# iom480ae register map
Registers are 32-bit, access not given, no defined reset value unless marked. A register's access mark holds for its fields unless they carry their own. Addresses are absolute; registers are grouped by the start of their names; [hi:lo] are bit positions; {n}, {i} and the like mark numbered series; 'fields as' and 'values as' point back to an identical list.

## SCS
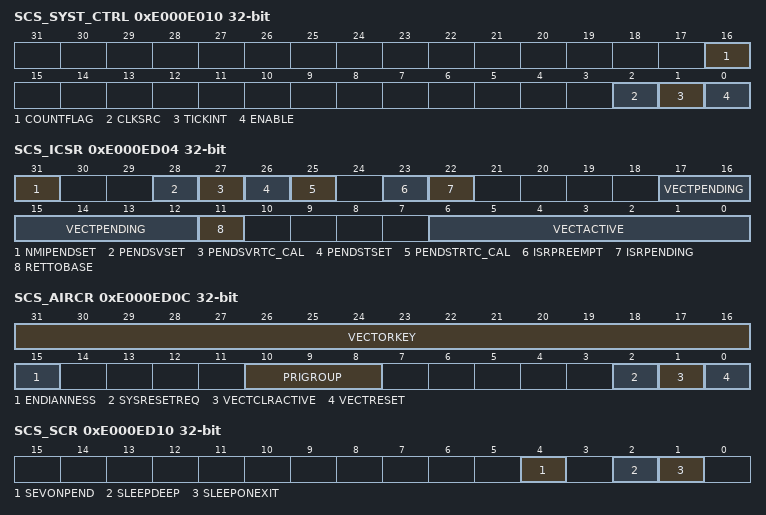
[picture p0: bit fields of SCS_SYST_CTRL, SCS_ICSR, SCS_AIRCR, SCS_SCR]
0xE000E010 SCS_SYST_CTRL
  [16] COUNTFLAG, [2] CLKSRC, [1] TICKINT, [0] ENABLE
0xE000E014 SCS_SYST_LOAD
  [23:0] RELOAD
0xE000E018 SCS_SYST_VAL
  [23:0] CURRENT
0xE000ED04 SCS_ICSR
  [31] NMIPENDSET, [28] PENDSVSET, [27] PENDSVRTC_CAL, [26] PENDSTSET, [25] PENDSTRTC_CAL, [23] ISRPREEMPT, [22] ISRPENDING, [17:12] VECTPENDING, [11] RETTOBASE, [6:0] VECTACTIVE
0xE000ED0C SCS_AIRCR
  [31:16] VECTORKEY, [15] ENDIANNESS, [10:8] PRIGROUP, [2] SYSRESETREQ, [1] VECTCLRACTIVE, [0] VECTRESET
0xE000ED10 SCS_SCR
  [4] SEVONPEND, [2] SLEEPDEEP, [1] SLEEPONEXIT
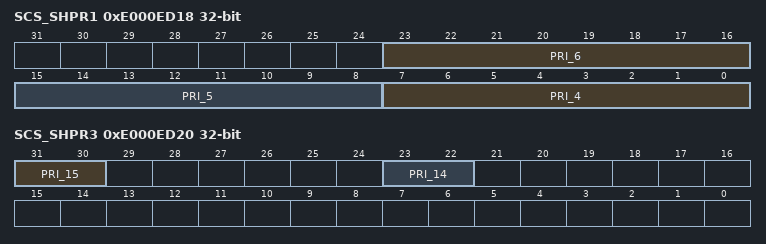
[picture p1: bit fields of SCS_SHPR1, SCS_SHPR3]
0xE000ED18 SCS_SHPR1
  [23:16] PRI_6, [15:8] PRI_5, [7:0] PRI_4
0xE000ED1C SCS_SHPR2
  [31:30] PRI_11
0xE000ED20 SCS_SHPR3
  [31:30] PRI_15, [23:22] PRI_14

## NVIC
{0xE000E100+4i} NVIC_NVIC_ISER{i} (i=0..2)
{0xE000E180+4i} NVIC_NVIC_ICER{i} (i=0..2)
{0xE000E200+4i} NVIC_NVIC_ISPR{i} (i=0..2)
{0xE000E280+4i} NVIC_NVIC_ICPR{i} (i=0..2)
{0xE000E300+4i} NVIC_NVIC_IABR{i} (i=0..2)
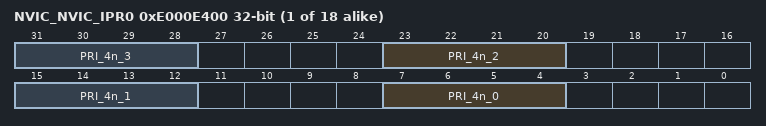
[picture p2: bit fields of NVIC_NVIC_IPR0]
{0xE000E400+4i} NVIC_NVIC_IPR{i} (i=0..17)
  [8n+7:8n+4] PRI_4n_{n} (n=0..3)
0xE000EF00 NVIC_STIR
  [8:0] INTID

## NMI
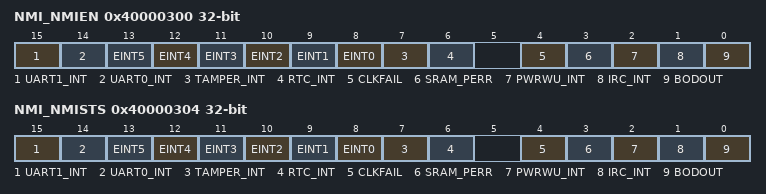
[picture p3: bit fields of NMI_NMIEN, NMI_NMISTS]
0x40000300 NMI_NMIEN
  [15] UART1_INT, [14] UART0_INT, [n+8] EINT{n} (n=0..5), [7] TAMPER_INT, [6] RTC_INT, [4] CLKFAIL, [3] SRAM_PERR, [2] PWRWU_INT, [1] IRC_INT, [0] BODOUT
0x40000304 NMI_NMISTS
  fields as NMI_NMIEN

## CLK
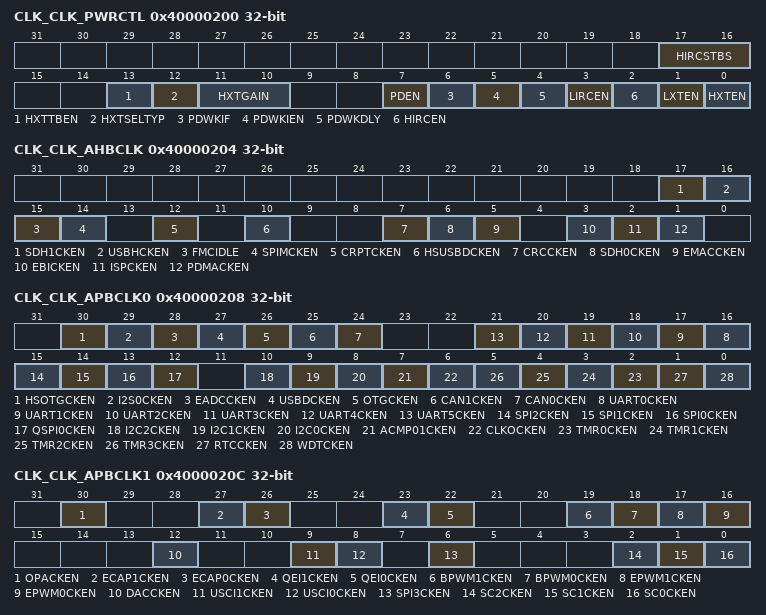
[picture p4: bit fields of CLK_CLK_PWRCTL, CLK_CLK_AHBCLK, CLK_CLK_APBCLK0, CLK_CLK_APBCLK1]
0x40000200 CLK_CLK_PWRCTL
  [17:16] HIRCSTBS, [13] HXTTBEN, [12] HXTSELTYP, [11:10] HXTGAIN, [7] PDEN, [6] PDWKIF, [5] PDWKIEN, [4] PDWKDLY, [3] LIRCEN, [2] HIRCEN, [1] LXTEN, [0] HXTEN
0x40000204 CLK_CLK_AHBCLK
  [17] SDH1CKEN, [16] USBHCKEN, [15] FMCIDLE, [14] SPIMCKEN, [12] CRPTCKEN, [10] HSUSBDCKEN, [7] CRCCKEN, [6] SDH0CKEN, [5] EMACCKEN, [3] EBICKEN, [2] ISPCKEN, [1] PDMACKEN
0x40000208 CLK_CLK_APBCLK0
  [30] HSOTGCKEN, [29] I2S0CKEN, [28] EADCCKEN, [27] USBDCKEN, [26] OTGCKEN, [25] CAN1CKEN, [24] CAN0CKEN, [n+16] UART{n}CKEN (n=0..5), [15] SPI2CKEN, [14] SPI1CKEN, [13] SPI0CKEN, [12] QSPI0CKEN, [10] I2C2CKEN, [9] I2C1CKEN, [8] I2C0CKEN, [7] ACMP01CKEN, [6] CLKOCKEN, [n+2] TMR{n}CKEN (n=0..3), [1] RTCCKEN, [0] WDTCKEN
0x4000020C CLK_CLK_APBCLK1
  [30] OPACKEN, [27] ECAP1CKEN, [26] ECAP0CKEN, [23] QEI1CKEN, [22] QEI0CKEN, [19] BPWM1CKEN, [18] BPWM0CKEN, [17] EPWM1CKEN, [16] EPWM0CKEN, [12] DACCKEN, [9] USCI1CKEN, [8] USCI0CKEN, [6] SPI3CKEN, [2] SC2CKEN, [1] SC1CKEN, [0] SC0CKEN
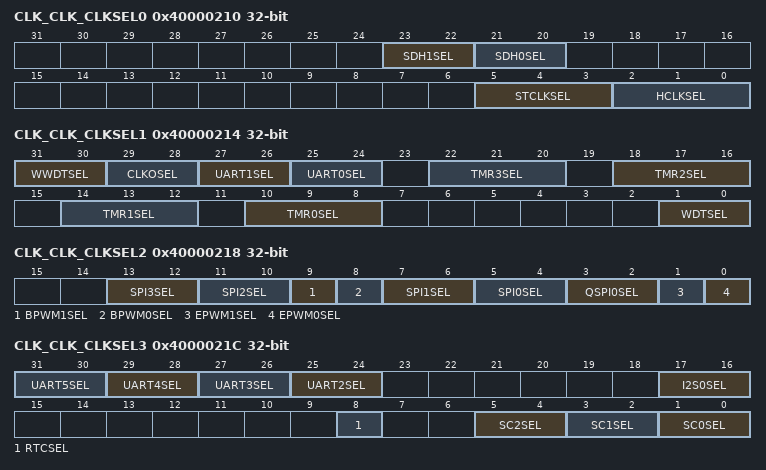
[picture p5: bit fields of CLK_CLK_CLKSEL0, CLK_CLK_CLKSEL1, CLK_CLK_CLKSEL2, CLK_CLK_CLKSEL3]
0x40000210 CLK_CLK_CLKSEL0
  [23:22] SDH1SEL, [21:20] SDH0SEL, [5:3] STCLKSEL, [2:0] HCLKSEL
0x40000214 CLK_CLK_CLKSEL1
  [31:30] WWDTSEL, [29:28] CLKOSEL, [27:26] UART1SEL, [25:24] UART0SEL, [4n+10:4n+8] TMR{n}SEL (n=0..3), [1:0] WDTSEL
0x40000218 CLK_CLK_CLKSEL2
  [13:12] SPI3SEL, [11:10] SPI2SEL, [9] BPWM1SEL, [8] BPWM0SEL, [7:6] SPI1SEL, [5:4] SPI0SEL, [3:2] QSPI0SEL, [1] EPWM1SEL, [0] EPWM0SEL
0x4000021C CLK_CLK_CLKSEL3
  [2n+21:2n+20] UART{n}SEL (n=2..5), [17:16] I2S0SEL, [8] RTCSEL, [5:4] SC2SEL, [3:2] SC1SEL, [1:0] SC0SEL
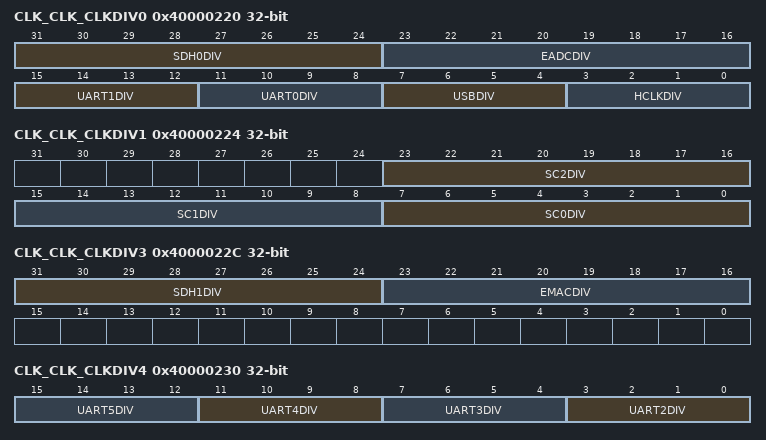
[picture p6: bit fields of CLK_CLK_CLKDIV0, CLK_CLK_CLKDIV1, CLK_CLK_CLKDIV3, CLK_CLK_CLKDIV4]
0x40000220 CLK_CLK_CLKDIV0
  [31:24] SDH0DIV, [23:16] EADCDIV, [15:12] UART1DIV, [11:8] UART0DIV, [7:4] USBDIV, [3:0] HCLKDIV
0x40000224 CLK_CLK_CLKDIV1
  [23:16] SC2DIV, [15:8] SC1DIV, [7:0] SC0DIV
0x4000022C CLK_CLK_CLKDIV3
  [31:24] SDH1DIV, [23:16] EMACDIV
0x40000230 CLK_CLK_CLKDIV4
  [4n-5:4n-8] UART{n}DIV (n=2..5)
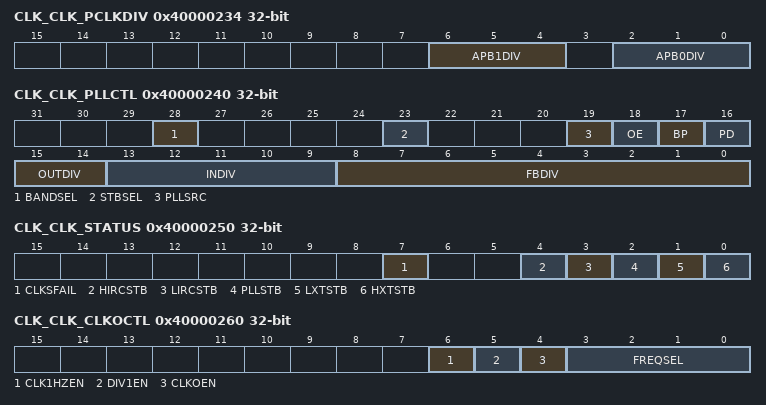
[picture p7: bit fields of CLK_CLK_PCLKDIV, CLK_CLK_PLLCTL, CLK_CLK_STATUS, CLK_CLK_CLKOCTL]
0x40000234 CLK_CLK_PCLKDIV
  [6:4] APB1DIV, [2:0] APB0DIV
0x40000240 CLK_CLK_PLLCTL
  [28] BANDSEL, [23] STBSEL, [19] PLLSRC, [18] OE, [17] BP, [16] PD, [15:14] OUTDIV, [13:9] INDIV, [8:0] FBDIV
0x40000250 CLK_CLK_STATUS
  [7] CLKSFAIL, [4] HIRCSTB, [3] LIRCSTB, [2] PLLSTB, [1] LXTSTB, [0] HXTSTB
0x40000260 CLK_CLK_CLKOCTL
  [6] CLK1HZEN, [5] DIV1EN, [4] CLKOEN, [3:0] FREQSEL
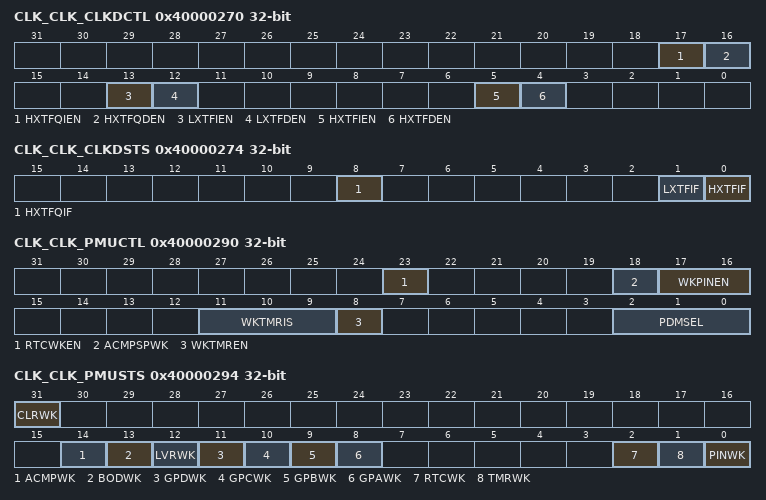
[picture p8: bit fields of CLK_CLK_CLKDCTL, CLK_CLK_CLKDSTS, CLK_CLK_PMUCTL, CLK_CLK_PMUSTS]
0x40000270 CLK_CLK_CLKDCTL
  [17] HXTFQIEN, [16] HXTFQDEN, [13] LXTFIEN, [12] LXTFDEN, [5] HXTFIEN, [4] HXTFDEN
0x40000274 CLK_CLK_CLKDSTS
  [8] HXTFQIF, [1] LXTFIF, [0] HXTFIF
0x40000278 CLK_CLK_CDUPB
  [9:0] UPERBD
0x4000027C CLK_CLK_CDLOWB
  [9:0] LOWERBD
0x40000290 CLK_CLK_PMUCTL
  [23] RTCWKEN, [18] ACMPSPWK, [17:16] WKPINEN, [11:9] WKTMRIS, [8] WKTMREN, [2:0] PDMSEL
0x40000294 CLK_CLK_PMUSTS
  [31] CLRWK, [14] ACMPWK, [13] BODWK, [12] LVRWK, [11] GPDWK, [10] GPCWK, [9] GPBWK, [8] GPAWK, [2] RTCWK, [1] TMRWK, [0] PINWK
0x40000298 CLK_CLK_LDOCTL
  [18] PDBIASEN
0x4000029C CLK_CLK_SWKDBCTL
  [3:0] SWKDBCLKSEL
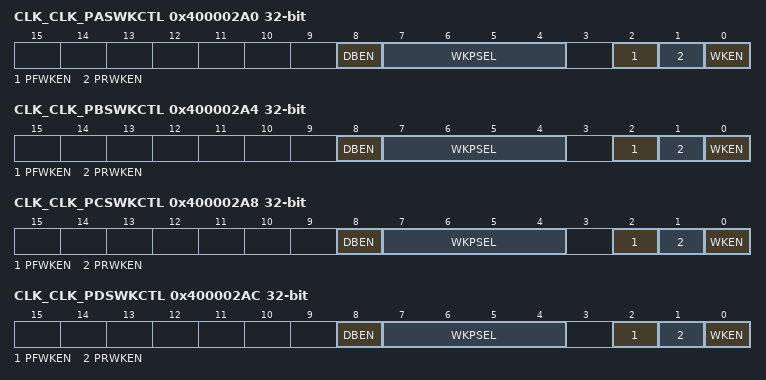
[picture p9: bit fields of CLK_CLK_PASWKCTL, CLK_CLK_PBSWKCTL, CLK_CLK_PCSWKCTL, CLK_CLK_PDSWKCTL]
0x400002A0 CLK_CLK_PASWKCTL
  [8] DBEN, [7:4] WKPSEL, [2] PFWKEN, [1] PRWKEN, [0] WKEN
0x400002A4 CLK_CLK_PBSWKCTL
  [8] DBEN, [7:4] WKPSEL, [2] PFWKEN, [1] PRWKEN, [0] WKEN
0x400002A8 CLK_CLK_PCSWKCTL
  [8] DBEN, [7:4] WKPSEL, [2] PFWKEN, [1] PRWKEN, [0] WKEN
0x400002AC CLK_CLK_PDSWKCTL
  [8] DBEN, [7:4] WKPSEL, [2] PFWKEN, [1] PRWKEN, [0] WKEN
0x400002B0 CLK_CLK_IOPDCTL
  [0] IOHR
